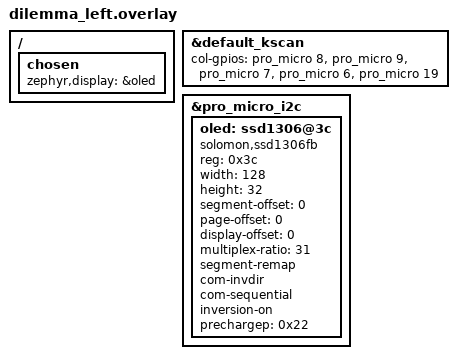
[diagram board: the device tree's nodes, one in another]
/*
 * Copyright (c) 2021 The ZMK Contributors
 *
 * SPDX-License-Identifier: MIT
 */

#include "dilemma.dtsi"

/ {
    chosen {
        zephyr,display = &oled;
    };
};

&default_kscan {
	col-gpios
		= <&pro_micro 8  (GPIO_ACTIVE_HIGH | GPIO_PULL_DOWN)>
		, <&pro_micro 9  (GPIO_ACTIVE_HIGH | GPIO_PULL_DOWN)>
		, <&pro_micro 7  (GPIO_ACTIVE_HIGH | GPIO_PULL_DOWN)>
		, <&pro_micro 6  (GPIO_ACTIVE_HIGH | GPIO_PULL_DOWN)>
		, <&pro_micro 19 (GPIO_ACTIVE_HIGH | GPIO_PULL_DOWN)>
		;
};

&pro_micro_i2c {
    status = "okay";

    oled: ssd1306@3c {
        compatible = "solomon,ssd1306fb";
        reg = <0x3c>;
        width = <128>;
        height = <32>;
        segment-offset = <0>;
        page-offset = <0>;
        display-offset = <0>;
        multiplex-ratio = <31>;
        segment-remap;
        com-invdir;
        com-sequential;
        inversion-on;
        prechargep = <0x22>;
    };
};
